VERSION "Accord 9G AU Radar BUS 1"

NS_ :

BS_:

BU_: RADAR ADAS EON

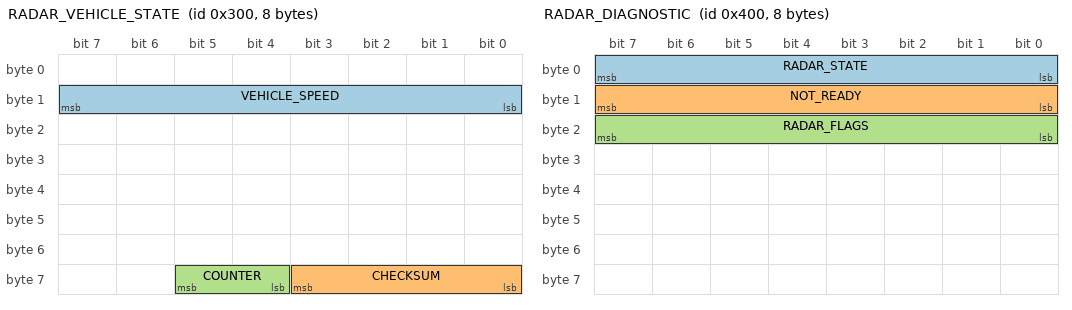
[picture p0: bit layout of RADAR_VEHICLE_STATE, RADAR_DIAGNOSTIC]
BO_ 768 RADAR_VEHICLE_STATE: 8 ADAS
 SG_ VEHICLE_SPEED : 15|8@0+ (1,0) [0|255] "kph" RADAR
 SG_ CHECKSUM : 59|4@0+ (1,0) [0|15] "" RADAR
 SG_ COUNTER : 61|2@0+ (1,0) [0|3] "" RADAR

BO_ 769 RADAR_VEHICLE_STATE2: 8 ADAS

BO_ 1024 RADAR_DIAGNOSTIC: 8 RADAR
 SG_ RADAR_STATE : 7|8@0+ (1,0) [0|255] "" EON
 SG_ NOT_READY : 15|8@0+ (1,0) [0|255] "" EON
 SG_ RADAR_FLAGS : 23|8@0+ (1,0) [0|255] "" EON

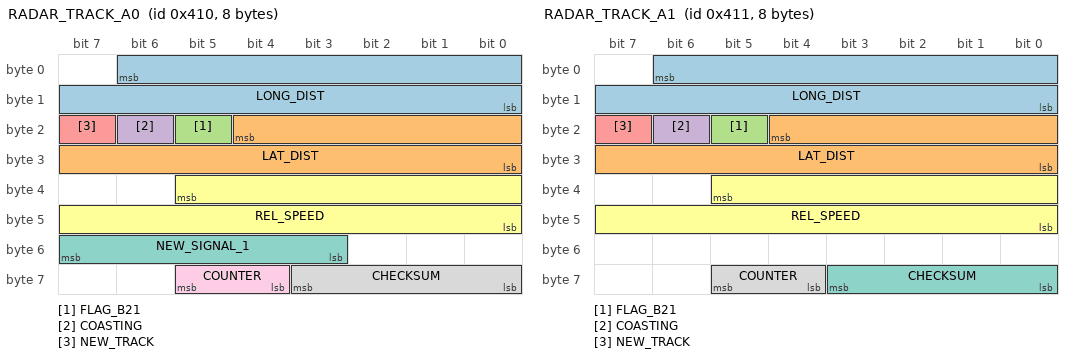
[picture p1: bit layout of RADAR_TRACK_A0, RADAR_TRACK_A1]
BO_ 1040 RADAR_TRACK_A0: 8 RADAR
 SG_ LONG_DIST : 6|15@0+ (0.0078125,0) [0|255.99] "m" EON
 SG_ LAT_DIST : 20|13@0- (0.0078125,0) [-32|32] "m" EON
 SG_ FLAG_B21 : 21|1@0+ (1,0) [0|1] "" EON
 SG_ COASTING : 22|1@0+ (1,0) [0|1] "" EON
 SG_ NEW_TRACK : 23|1@0+ (1,0) [0|1] "" EON
 SG_ REL_SPEED : 37|14@0- (0.015625,0) [-128|128] "m/s" EON
 SG_ NEW_SIGNAL_1 : 55|5@0+ (1,0) [0|31] "" XXX
 SG_ CHECKSUM : 59|4@0+ (1,0) [0|15] "" EON
 SG_ COUNTER : 61|2@0+ (1,0) [0|3] "" EON

BO_ 1041 RADAR_TRACK_A1: 8 RADAR
 SG_ LONG_DIST : 6|15@0+ (0.0078125,0) [0|255.99] "m" EON
 SG_ LAT_DIST : 20|13@0- (0.0078125,0) [-32|32] "m" EON
 SG_ FLAG_B21 : 21|1@0+ (1,0) [0|1] "" EON
 SG_ COASTING : 22|1@0+ (1,0) [0|1] "" EON
 SG_ NEW_TRACK : 23|1@0+ (1,0) [0|1] "" EON
 SG_ REL_SPEED : 37|14@0- (0.015625,0) [-128|128] "m/s" EON
 SG_ CHECKSUM : 59|4@0+ (1,0) [0|15] "" EON
 SG_ COUNTER : 61|2@0+ (1,0) [0|3] "" EON

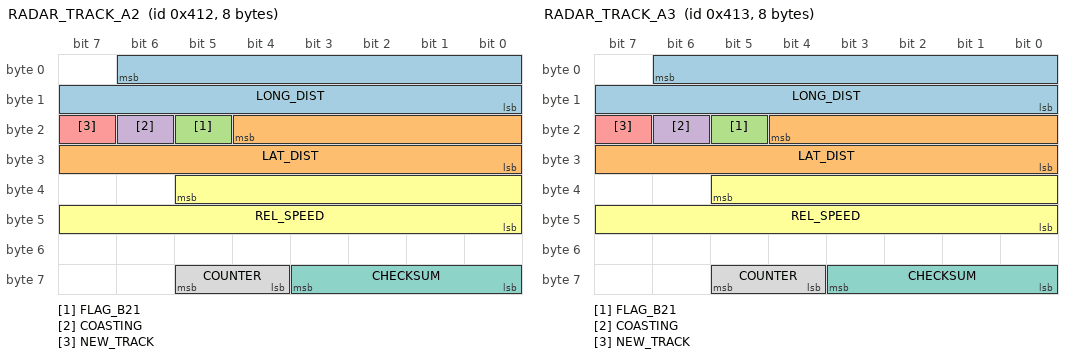
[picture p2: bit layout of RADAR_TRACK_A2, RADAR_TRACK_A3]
BO_ 1042 RADAR_TRACK_A2: 8 RADAR
 SG_ LONG_DIST : 6|15@0+ (0.0078125,0) [0|255.99] "m" EON
 SG_ LAT_DIST : 20|13@0- (0.0078125,0) [-32|32] "m" EON
 SG_ FLAG_B21 : 21|1@0+ (1,0) [0|1] "" EON
 SG_ COASTING : 22|1@0+ (1,0) [0|1] "" EON
 SG_ NEW_TRACK : 23|1@0+ (1,0) [0|1] "" EON
 SG_ REL_SPEED : 37|14@0- (0.015625,0) [-128|128] "m/s" EON
 SG_ CHECKSUM : 59|4@0+ (1,0) [0|15] "" EON
 SG_ COUNTER : 61|2@0+ (1,0) [0|3] "" EON

BO_ 1043 RADAR_TRACK_A3: 8 RADAR
 SG_ LONG_DIST : 6|15@0+ (0.0078125,0) [0|255.99] "m" EON
 SG_ LAT_DIST : 20|13@0- (0.0078125,0) [-32|32] "m" EON
 SG_ FLAG_B21 : 21|1@0+ (1,0) [0|1] "" EON
 SG_ COASTING : 22|1@0+ (1,0) [0|1] "" EON
 SG_ NEW_TRACK : 23|1@0+ (1,0) [0|1] "" EON
 SG_ REL_SPEED : 37|14@0- (0.015625,0) [-128|128] "m/s" EON
 SG_ CHECKSUM : 59|4@0+ (1,0) [0|15] "" EON
 SG_ COUNTER : 61|2@0+ (1,0) [0|3] "" EON

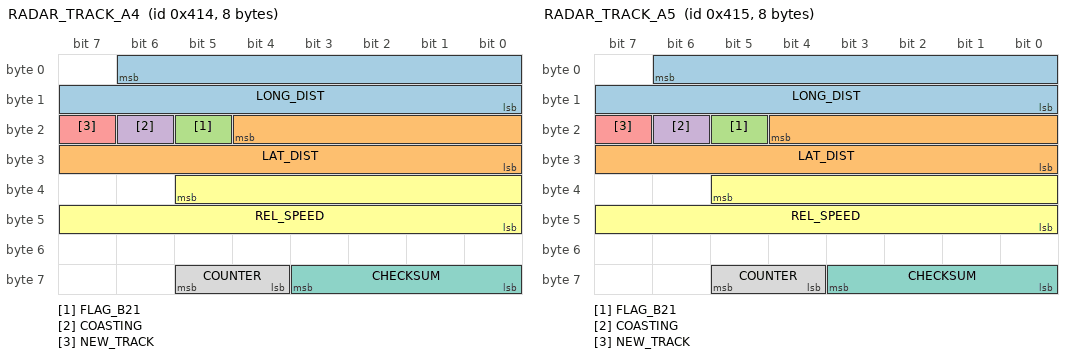
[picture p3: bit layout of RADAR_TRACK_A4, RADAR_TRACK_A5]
BO_ 1044 RADAR_TRACK_A4: 8 RADAR
 SG_ LONG_DIST : 6|15@0+ (0.0078125,0) [0|255.99] "m" EON
 SG_ LAT_DIST : 20|13@0- (0.0078125,0) [-32|32] "m" EON
 SG_ FLAG_B21 : 21|1@0+ (1,0) [0|1] "" EON
 SG_ COASTING : 22|1@0+ (1,0) [0|1] "" EON
 SG_ NEW_TRACK : 23|1@0+ (1,0) [0|1] "" EON
 SG_ REL_SPEED : 37|14@0- (0.015625,0) [-128|128] "m/s" EON
 SG_ CHECKSUM : 59|4@0+ (1,0) [0|15] "" EON
 SG_ COUNTER : 61|2@0+ (1,0) [0|3] "" EON

BO_ 1045 RADAR_TRACK_A5: 8 RADAR
 SG_ LONG_DIST : 6|15@0+ (0.0078125,0) [0|255.99] "m" EON
 SG_ LAT_DIST : 20|13@0- (0.0078125,0) [-32|32] "m" EON
 SG_ FLAG_B21 : 21|1@0+ (1,0) [0|1] "" EON
 SG_ COASTING : 22|1@0+ (1,0) [0|1] "" EON
 SG_ NEW_TRACK : 23|1@0+ (1,0) [0|1] "" EON
 SG_ REL_SPEED : 37|14@0- (0.015625,0) [-128|128] "m/s" EON
 SG_ CHECKSUM : 59|4@0+ (1,0) [0|15] "" EON
 SG_ COUNTER : 61|2@0+ (1,0) [0|3] "" EON

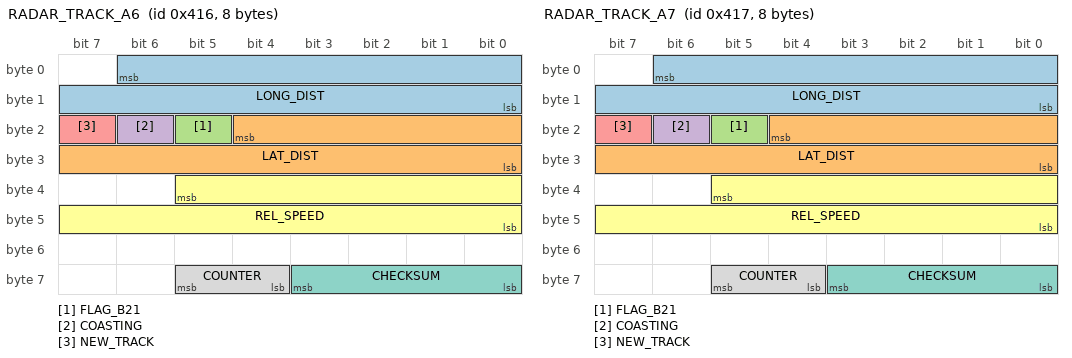
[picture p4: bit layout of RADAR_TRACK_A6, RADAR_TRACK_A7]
BO_ 1046 RADAR_TRACK_A6: 8 RADAR
 SG_ LONG_DIST : 6|15@0+ (0.0078125,0) [0|255.99] "m" EON
 SG_ LAT_DIST : 20|13@0- (0.0078125,0) [-32|32] "m" EON
 SG_ FLAG_B21 : 21|1@0+ (1,0) [0|1] "" EON
 SG_ COASTING : 22|1@0+ (1,0) [0|1] "" EON
 SG_ NEW_TRACK : 23|1@0+ (1,0) [0|1] "" EON
 SG_ REL_SPEED : 37|14@0- (0.015625,0) [-128|128] "m/s" EON
 SG_ CHECKSUM : 59|4@0+ (1,0) [0|15] "" EON
 SG_ COUNTER : 61|2@0+ (1,0) [0|3] "" EON

BO_ 1047 RADAR_TRACK_A7: 8 RADAR
 SG_ LONG_DIST : 6|15@0+ (0.0078125,0) [0|255.99] "m" EON
 SG_ LAT_DIST : 20|13@0- (0.0078125,0) [-32|32] "m" EON
 SG_ FLAG_B21 : 21|1@0+ (1,0) [0|1] "" EON
 SG_ COASTING : 22|1@0+ (1,0) [0|1] "" EON
 SG_ NEW_TRACK : 23|1@0+ (1,0) [0|1] "" EON
 SG_ REL_SPEED : 37|14@0- (0.015625,0) [-128|128] "m/s" EON
 SG_ CHECKSUM : 59|4@0+ (1,0) [0|15] "" EON
 SG_ COUNTER : 61|2@0+ (1,0) [0|3] "" EON

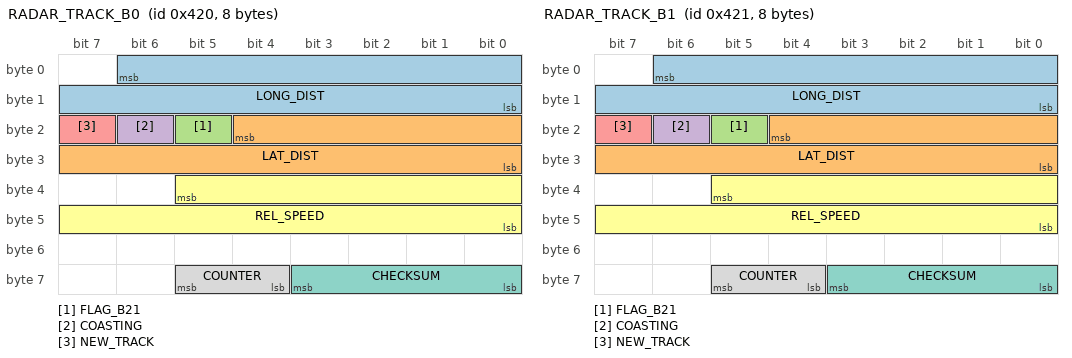
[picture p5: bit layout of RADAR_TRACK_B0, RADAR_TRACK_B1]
BO_ 1056 RADAR_TRACK_B0: 8 RADAR
 SG_ LONG_DIST : 6|15@0+ (0.0078125,0) [0|255.99] "m" EON
 SG_ LAT_DIST : 20|13@0- (0.0078125,0) [-32|32] "m" EON
 SG_ FLAG_B21 : 21|1@0+ (1,0) [0|1] "" EON
 SG_ COASTING : 22|1@0+ (1,0) [0|1] "" EON
 SG_ NEW_TRACK : 23|1@0+ (1,0) [0|1] "" EON
 SG_ REL_SPEED : 37|14@0- (0.015625,0) [-128|128] "m/s" EON
 SG_ CHECKSUM : 59|4@0+ (1,0) [0|15] "" EON
 SG_ COUNTER : 61|2@0+ (1,0) [0|3] "" EON

BO_ 1057 RADAR_TRACK_B1: 8 RADAR
 SG_ LONG_DIST : 6|15@0+ (0.0078125,0) [0|255.99] "m" EON
 SG_ LAT_DIST : 20|13@0- (0.0078125,0) [-32|32] "m" EON
 SG_ FLAG_B21 : 21|1@0+ (1,0) [0|1] "" EON
 SG_ COASTING : 22|1@0+ (1,0) [0|1] "" EON
 SG_ NEW_TRACK : 23|1@0+ (1,0) [0|1] "" EON
 SG_ REL_SPEED : 37|14@0- (0.015625,0) [-128|128] "m/s" EON
 SG_ CHECKSUM : 59|4@0+ (1,0) [0|15] "" EON
 SG_ COUNTER : 61|2@0+ (1,0) [0|3] "" EON

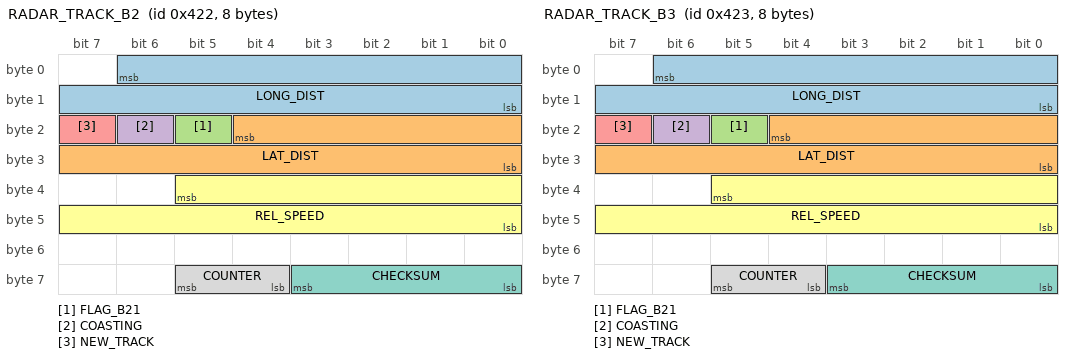
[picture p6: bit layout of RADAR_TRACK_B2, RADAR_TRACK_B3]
BO_ 1058 RADAR_TRACK_B2: 8 RADAR
 SG_ LONG_DIST : 6|15@0+ (0.0078125,0) [0|255.99] "m" EON
 SG_ LAT_DIST : 20|13@0- (0.0078125,0) [-32|32] "m" EON
 SG_ FLAG_B21 : 21|1@0+ (1,0) [0|1] "" EON
 SG_ COASTING : 22|1@0+ (1,0) [0|1] "" EON
 SG_ NEW_TRACK : 23|1@0+ (1,0) [0|1] "" EON
 SG_ REL_SPEED : 37|14@0- (0.015625,0) [-128|128] "m/s" EON
 SG_ CHECKSUM : 59|4@0+ (1,0) [0|15] "" EON
 SG_ COUNTER : 61|2@0+ (1,0) [0|3] "" EON

BO_ 1059 RADAR_TRACK_B3: 8 RADAR
 SG_ LONG_DIST : 6|15@0+ (0.0078125,0) [0|255.99] "m" EON
 SG_ LAT_DIST : 20|13@0- (0.0078125,0) [-32|32] "m" EON
 SG_ FLAG_B21 : 21|1@0+ (1,0) [0|1] "" EON
 SG_ COASTING : 22|1@0+ (1,0) [0|1] "" EON
 SG_ NEW_TRACK : 23|1@0+ (1,0) [0|1] "" EON
 SG_ REL_SPEED : 37|14@0- (0.015625,0) [-128|128] "m/s" EON
 SG_ CHECKSUM : 59|4@0+ (1,0) [0|15] "" EON
 SG_ COUNTER : 61|2@0+ (1,0) [0|3] "" EON

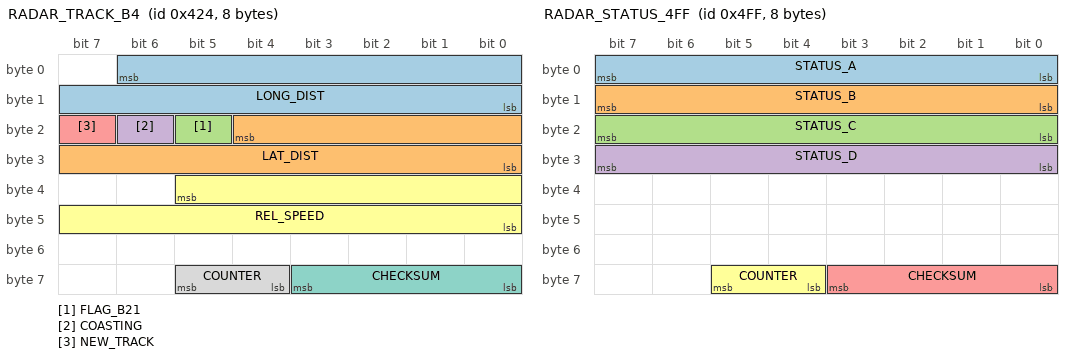
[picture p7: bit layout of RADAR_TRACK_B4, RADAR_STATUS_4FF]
BO_ 1060 RADAR_TRACK_B4: 8 RADAR
 SG_ LONG_DIST : 6|15@0+ (0.0078125,0) [0|255.99] "m" EON
 SG_ LAT_DIST : 20|13@0- (0.0078125,0) [-32|32] "m" EON
 SG_ FLAG_B21 : 21|1@0+ (1,0) [0|1] "" EON
 SG_ COASTING : 22|1@0+ (1,0) [0|1] "" EON
 SG_ NEW_TRACK : 23|1@0+ (1,0) [0|1] "" EON
 SG_ REL_SPEED : 37|14@0- (0.015625,0) [-128|128] "m/s" EON
 SG_ CHECKSUM : 59|4@0+ (1,0) [0|15] "" EON
 SG_ COUNTER : 61|2@0+ (1,0) [0|3] "" EON

BO_ 1279 RADAR_STATUS_4FF: 8 RADAR
 SG_ STATUS_A : 7|8@0+ (1,0) [0|255] "" EON
 SG_ STATUS_B : 15|8@0+ (1,0) [0|111] "" EON
 SG_ STATUS_C : 23|8@0+ (1,0) [0|255] "" EON
 SG_ STATUS_D : 31|8@0+ (1,0) [0|255] "" EON
 SG_ CHECKSUM : 59|4@0+ (1,0) [0|15] "" EON
 SG_ COUNTER : 61|2@0+ (1,0) [0|3] "" EON

CM_ SG_ 1040 REL_SPEED "Range rate, negative = closing. Scale 0.015625 m/s (1/64), measured 2026-10-09: on bus 1 d(LONG_DIST)/dt = 2.01-2.03 x the old 1/128 decode on routes 113 and 120 (A group; B 2.00-2.01 by median ratio), and a stationary object read -0.50 x vEgo at 1/128. The 1/128 scale this file carried until then halved every radar vRel. 14-bit signed: byte 4 bits 7:6 are never set. Same on all 13 track messages.";
CM_ SG_ 1041 REL_SPEED "Range rate, negative = closing, 0.015625 m/s: see 1040 REL_SPEED.";
CM_ SG_ 1042 REL_SPEED "Range rate, negative = closing, 0.015625 m/s: see 1040 REL_SPEED.";
CM_ SG_ 1043 REL_SPEED "Range rate, negative = closing, 0.015625 m/s: see 1040 REL_SPEED.";
CM_ SG_ 1044 REL_SPEED "Range rate, negative = closing, 0.015625 m/s: see 1040 REL_SPEED.";
CM_ SG_ 1045 REL_SPEED "Range rate, negative = closing, 0.015625 m/s: see 1040 REL_SPEED.";
CM_ SG_ 1046 REL_SPEED "Range rate, negative = closing, 0.015625 m/s: see 1040 REL_SPEED.";
CM_ SG_ 1047 REL_SPEED "Range rate, negative = closing, 0.015625 m/s: see 1040 REL_SPEED.";
CM_ SG_ 1056 REL_SPEED "Range rate, negative = closing, 0.015625 m/s: see 1040 REL_SPEED.";
CM_ SG_ 1057 REL_SPEED "Range rate, negative = closing, 0.015625 m/s: see 1040 REL_SPEED.";
CM_ SG_ 1058 REL_SPEED "Range rate, negative = closing, 0.015625 m/s: see 1040 REL_SPEED.";
CM_ SG_ 1059 REL_SPEED "Range rate, negative = closing, 0.015625 m/s: see 1040 REL_SPEED.";
CM_ SG_ 1060 REL_SPEED "Range rate, negative = closing, 0.015625 m/s: see 1040 REL_SPEED.";
CM_ SG_ 1040 LONG_DIST "Range, 0.0078125 m (1/128), 0-255.98 m. Raw 0x7FFF (255.9921875) is an EMPTY slot: the only empty pattern in 9.9 M logged frames, and real returns reach 255.8 m, so the empty test is raw == 0x7FFF, not a range limit (radar_interface.py tested LONG_DIST < 255 until 2026-10-24). Same on all 13 track messages.";
CM_ SG_ 1041 LONG_DIST "Range, 1/128 m; raw 0x7FFF is an empty slot: see 1040 LONG_DIST.";
CM_ SG_ 1042 LONG_DIST "Range, 1/128 m; raw 0x7FFF is an empty slot: see 1040 LONG_DIST.";
CM_ SG_ 1043 LONG_DIST "Range, 1/128 m; raw 0x7FFF is an empty slot: see 1040 LONG_DIST.";
CM_ SG_ 1044 LONG_DIST "Range, 1/128 m; raw 0x7FFF is an empty slot: see 1040 LONG_DIST.";
CM_ SG_ 1045 LONG_DIST "Range, 1/128 m; raw 0x7FFF is an empty slot: see 1040 LONG_DIST.";
CM_ SG_ 1046 LONG_DIST "Range, 1/128 m; raw 0x7FFF is an empty slot: see 1040 LONG_DIST.";
CM_ SG_ 1047 LONG_DIST "Range, 1/128 m; raw 0x7FFF is an empty slot: see 1040 LONG_DIST.";
CM_ SG_ 1056 LONG_DIST "Range, 1/128 m; raw 0x7FFF is an empty slot: see 1040 LONG_DIST.";
CM_ SG_ 1057 LONG_DIST "Range, 1/128 m; raw 0x7FFF is an empty slot: see 1040 LONG_DIST.";
CM_ SG_ 1058 LONG_DIST "Range, 1/128 m; raw 0x7FFF is an empty slot: see 1040 LONG_DIST.";
CM_ SG_ 1059 LONG_DIST "Range, 1/128 m; raw 0x7FFF is an empty slot: see 1040 LONG_DIST.";
CM_ SG_ 1060 LONG_DIST "Range, 1/128 m; raw 0x7FFF is an empty slot: see 1040 LONG_DIST.";
CM_ SG_ 1040 NEW_TRACK "1 = the radar has put a new object in this slot. Set on two frames in a row, the second frame is another new object 92% of the time (1,467 repeats on 6 routes, 2026-10-24) and the same object otherwise; radar_interface.py gives a new trackId on a rising edge, or on a held 1 whose frame does not continue the slot's object. Same on all 13 track messages.";
CM_ SG_ 1041 NEW_TRACK "1 = a new object in this slot: see 1040 NEW_TRACK.";
CM_ SG_ 1042 NEW_TRACK "1 = a new object in this slot: see 1040 NEW_TRACK.";
CM_ SG_ 1043 NEW_TRACK "1 = a new object in this slot: see 1040 NEW_TRACK.";
CM_ SG_ 1044 NEW_TRACK "1 = a new object in this slot: see 1040 NEW_TRACK.";
CM_ SG_ 1045 NEW_TRACK "1 = a new object in this slot: see 1040 NEW_TRACK.";
CM_ SG_ 1046 NEW_TRACK "1 = a new object in this slot: see 1040 NEW_TRACK.";
CM_ SG_ 1047 NEW_TRACK "1 = a new object in this slot: see 1040 NEW_TRACK.";
CM_ SG_ 1056 NEW_TRACK "1 = a new object in this slot: see 1040 NEW_TRACK.";
CM_ SG_ 1057 NEW_TRACK "1 = a new object in this slot: see 1040 NEW_TRACK.";
CM_ SG_ 1058 NEW_TRACK "1 = a new object in this slot: see 1040 NEW_TRACK.";
CM_ SG_ 1059 NEW_TRACK "1 = a new object in this slot: see 1040 NEW_TRACK.";
CM_ SG_ 1060 NEW_TRACK "1 = a new object in this slot: see 1040 NEW_TRACK.";
CM_ SG_ 1040 COASTING "1 = the radar extrapolated this track this cycle instead of measuring it (RadarPoint.measured = 0). When set, REL_SPEED repeats the previous frame 89.6% of the time (33.6% when clear) and the range follows a constant-speed prediction to 0.04 m (0.10 m when clear). Set on 36-38% of stationary-clutter frames and 0.3% of camera-confirmed lead frames. Named FLAG_B22 until 2026-10-24. Same on all 13 track messages.";
CM_ SG_ 1041 COASTING "1 = extrapolated, not measured, this cycle: see 1040 COASTING.";
CM_ SG_ 1042 COASTING "1 = extrapolated, not measured, this cycle: see 1040 COASTING.";
CM_ SG_ 1043 COASTING "1 = extrapolated, not measured, this cycle: see 1040 COASTING.";
CM_ SG_ 1044 COASTING "1 = extrapolated, not measured, this cycle: see 1040 COASTING.";
CM_ SG_ 1045 COASTING "1 = extrapolated, not measured, this cycle: see 1040 COASTING.";
CM_ SG_ 1046 COASTING "1 = extrapolated, not measured, this cycle: see 1040 COASTING.";
CM_ SG_ 1047 COASTING "1 = extrapolated, not measured, this cycle: see 1040 COASTING.";
CM_ SG_ 1056 COASTING "1 = extrapolated, not measured, this cycle: see 1040 COASTING.";
CM_ SG_ 1057 COASTING "1 = extrapolated, not measured, this cycle: see 1040 COASTING.";
CM_ SG_ 1058 COASTING "1 = extrapolated, not measured, this cycle: see 1040 COASTING.";
CM_ SG_ 1059 COASTING "1 = extrapolated, not measured, this cycle: see 1040 COASTING.";
CM_ SG_ 1060 COASTING "1 = extrapolated, not measured, this cycle: see 1040 COASTING.";
